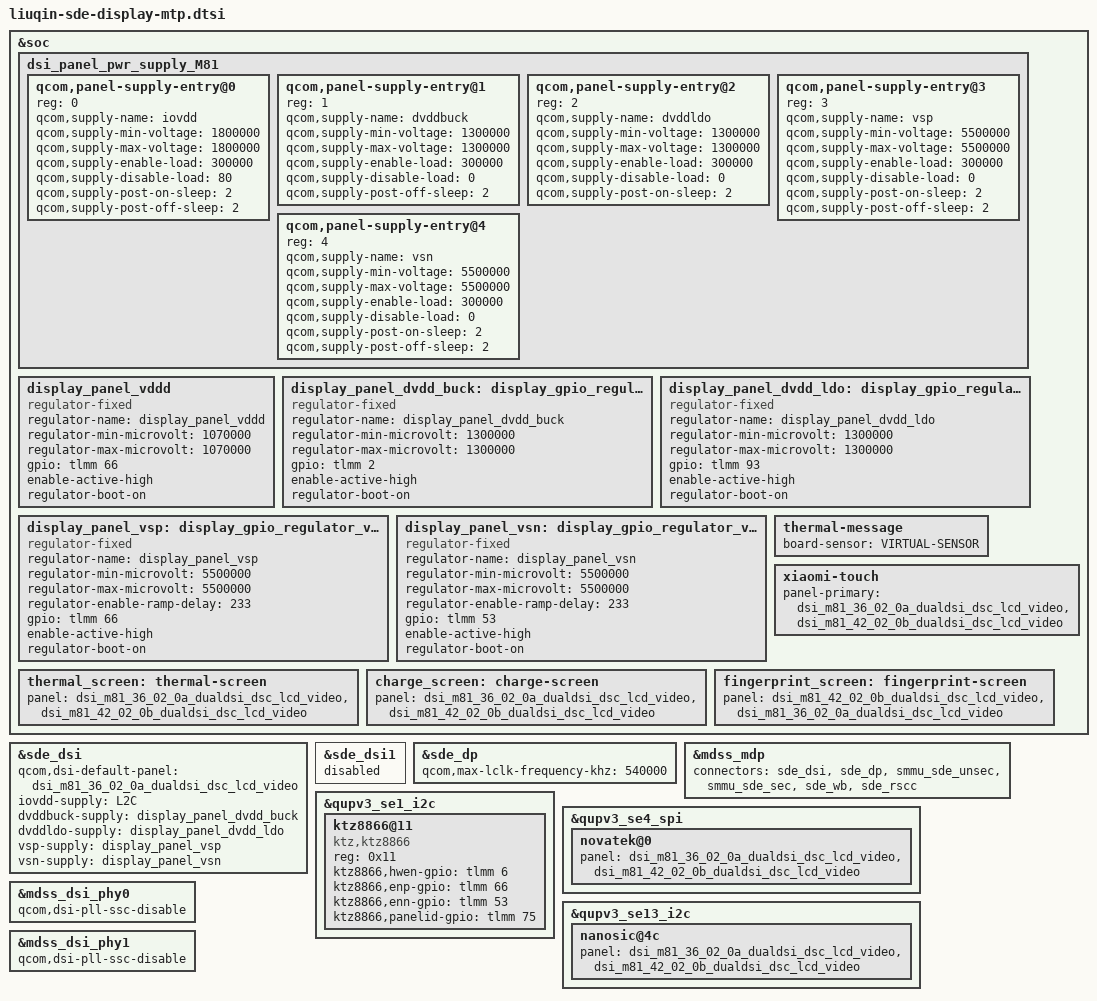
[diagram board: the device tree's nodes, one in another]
#include "cape-sde-display.dtsi"
#include "dsi-panel-m81-36-02-0a-dualdsi-dsc-lcd-video.dtsi"
#include "dsi-panel-m81-42-02-0b-dualdsi-dsc-lcd-video.dtsi"

/* M81 is a 1800 x 2880 dual-DSI LCD; each controller drives 900 pixels. */
&soc {
	dsi_panel_pwr_supply_M81: dsi_panel_pwr_supply_M81 {
		#address-cells = <1>;
		#size-cells = <0>;

		qcom,panel-supply-entry@0 {
			reg = <0>;
			qcom,supply-name = "iovdd";
			qcom,supply-min-voltage = <1800000>;
			qcom,supply-max-voltage = <1800000>;
			qcom,supply-enable-load = <300000>;
			qcom,supply-disable-load = <80>;
			qcom,supply-post-on-sleep = <2>;
			qcom,supply-post-off-sleep = <2>;
		};

		qcom,panel-supply-entry@1 {
			reg = <1>;
			qcom,supply-name = "dvddbuck";
			qcom,supply-min-voltage = <1300000>;
			qcom,supply-max-voltage = <1300000>;
			qcom,supply-enable-load = <300000>;
			qcom,supply-disable-load = <0>;
			qcom,supply-post-off-sleep = <2>;
		};

		qcom,panel-supply-entry@2 {
			reg = <2>;
			qcom,supply-name = "dvddldo";
			qcom,supply-min-voltage = <1300000>;
			qcom,supply-max-voltage = <1300000>;
			qcom,supply-enable-load = <300000>;
			qcom,supply-disable-load = <0>;
			qcom,supply-post-on-sleep = <2>;
		};

		qcom,panel-supply-entry@3 {
			reg = <3>;
			qcom,supply-name = "vsp";
			qcom,supply-min-voltage = <5500000>;
			qcom,supply-max-voltage = <5500000>;
			qcom,supply-enable-load = <300000>;
			qcom,supply-disable-load = <0>;
			qcom,supply-post-on-sleep = <2>;
			qcom,supply-post-off-sleep = <2>;
		};

		qcom,panel-supply-entry@4 {
			reg = <4>;
			qcom,supply-name = "vsn";
			qcom,supply-min-voltage = <5500000>;
			qcom,supply-max-voltage = <5500000>;
			qcom,supply-enable-load = <300000>;
			qcom,supply-disable-load = <0>;
			qcom,supply-post-on-sleep = <2>;
			qcom,supply-post-off-sleep = <2>;
		};
	};

	display_panel_vddd: display_panel_vddd {
		compatible = "regulator-fixed";
		regulator-name = "display_panel_vddd";
		regulator-min-microvolt = <1070000>;
		regulator-max-microvolt = <1070000>;
		gpio = <&tlmm 66 0>;
		enable-active-high;
		regulator-boot-on;
	};

	display_panel_dvdd_buck: display_gpio_regulator_dvdd_buck {
		compatible = "regulator-fixed";
		regulator-name = "display_panel_dvdd_buck";
		regulator-min-microvolt = <1300000>;
		regulator-max-microvolt = <1300000>;
		gpio = <&tlmm 2 0>;
		enable-active-high;
		regulator-boot-on;
	};

	display_panel_dvdd_ldo: display_gpio_regulator_dvdd_ldo {
		compatible = "regulator-fixed";
		regulator-name = "display_panel_dvdd_ldo";
		regulator-min-microvolt = <1300000>;
		regulator-max-microvolt = <1300000>;
		gpio = <&tlmm 93 0>;
		enable-active-high;
		regulator-boot-on;
	};

	display_panel_vsp: display_gpio_regulator_vsp {
		compatible = "regulator-fixed";
		regulator-name = "display_panel_vsp";
		regulator-min-microvolt = <5500000>;
		regulator-max-microvolt = <5500000>;
		regulator-enable-ramp-delay = <233>;
		gpio = <&tlmm 66 0>;
		enable-active-high;
		regulator-boot-on;
	};

	display_panel_vsn: display_gpio_regulator_vsn {
		compatible = "regulator-fixed";
		regulator-name = "display_panel_vsn";
		regulator-min-microvolt = <5500000>;
		regulator-max-microvolt = <5500000>;
		regulator-enable-ramp-delay = <233>;
		gpio = <&tlmm 53 0>;
		enable-active-high;
		regulator-boot-on;
	};
};

&sde_dsi {
	qcom,dsi-default-panel = <&dsi_m81_36_02_0a_dualdsi_dsc_lcd_video>;
	iovdd-supply = <&L2C>;
	dvddbuck-supply = <&display_panel_dvdd_buck>;
	dvddldo-supply = <&display_panel_dvdd_ldo>;
	vsp-supply = <&display_panel_vsp>;
	vsn-supply = <&display_panel_vsn>;
};

&sde_dsi1 {
	status = "disabled";
};

&sde_dp {
	status = "okay";
	qcom,max-lclk-frequency-khz = <540000>;
};

&mdss_mdp {
	connectors = <&sde_dsi &sde_dp &smmu_sde_unsec &smmu_sde_sec
		&sde_wb &sde_rscc>;
};

&qupv3_se1_i2c {
	status = "okay";

	ktz8866@11 {
		compatible = "ktz,ktz8866";
		reg = <0x11>;
		status = "okay";
		ktz8866,hwen-gpio = <&tlmm 6 0>;
		ktz8866,enp-gpio = <&tlmm 66 0>;
		ktz8866,enn-gpio = <&tlmm 53 0>;
		ktz8866,panelid-gpio = <&tlmm 75 0>;
	};
};

&qupv3_se4_spi {
	novatek@0 {
		panel = <&dsi_m81_36_02_0a_dualdsi_dsc_lcd_video
			&dsi_m81_42_02_0b_dualdsi_dsc_lcd_video>;
	};
};

&qupv3_se13_i2c {
	nanosic@4c {
		panel = <&dsi_m81_36_02_0a_dualdsi_dsc_lcd_video
			&dsi_m81_42_02_0b_dualdsi_dsc_lcd_video>;
	};
};

&soc {
	thermal-message {
		board-sensor = "VIRTUAL-SENSOR";
	};

	thermal_screen: thermal-screen {
		panel = <&dsi_m81_36_02_0a_dualdsi_dsc_lcd_video
			&dsi_m81_42_02_0b_dualdsi_dsc_lcd_video>;
	};

	charge_screen: charge-screen {
		panel = <&dsi_m81_36_02_0a_dualdsi_dsc_lcd_video
			&dsi_m81_42_02_0b_dualdsi_dsc_lcd_video>;
	};

	xiaomi-touch {
		panel-primary = <&dsi_m81_36_02_0a_dualdsi_dsc_lcd_video
			&dsi_m81_42_02_0b_dualdsi_dsc_lcd_video>;
	};

	/* Side fingerprint still consumes panel blank/unblank notifications. */
	fingerprint_screen: fingerprint-screen {
		panel = <&dsi_m81_42_02_0b_dualdsi_dsc_lcd_video
			&dsi_m81_36_02_0a_dualdsi_dsc_lcd_video>;
	};
};

&mdss_dsi_phy0 {
	qcom,dsi-pll-ssc-disable;
};

&mdss_dsi_phy1 {
	qcom,dsi-pll-ssc-disable;
};
